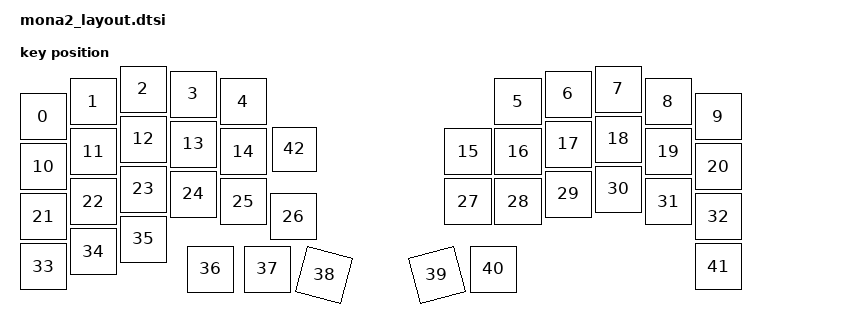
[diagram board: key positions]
// Generated by scripts/keymap.sh: the shield's physical layout plus the wheel, for drawing only.

/ {
physical_layout0: physical_layout_0 {
        compatible = "zmk,physical-layout";
        display-name = "moNa2";

        kscan = <&kscan0>;
        transform = <&default_transform>;

        keys  //                     w   h    x    y     rot    rx    ry
            = <&key_physical_attrs 100 100    0   55       0     0     0>
            , <&key_physical_attrs 100 100  100   25       0     0     0>
            , <&key_physical_attrs 100 100  200    0       0     0     0>
            , <&key_physical_attrs 100 100  300   10       0     0     0>
            , <&key_physical_attrs 100 100  400   25       0     0     0>
            , <&key_physical_attrs 100 100  950   25       0     0     0>
            , <&key_physical_attrs 100 100 1050   10       0     0     0>
            , <&key_physical_attrs 100 100 1150    0       0     0     0>
            , <&key_physical_attrs 100 100 1250   25       0     0     0>
            , <&key_physical_attrs 100 100 1350   55       0     0     0>
            , <&key_physical_attrs 100 100    0  155       0     0     0>
            , <&key_physical_attrs 100 100  100  125       0     0     0>
            , <&key_physical_attrs 100 100  200  100       0     0     0>
            , <&key_physical_attrs 100 100  300  110       0     0     0>
            , <&key_physical_attrs 100 100  400  125       0     0     0>
            , <&key_physical_attrs 100 100  850  125       0     0     0>
            , <&key_physical_attrs 100 100  950  125       0     0     0>
            , <&key_physical_attrs 100 100 1050  110       0     0     0>
            , <&key_physical_attrs 100 100 1150  100       0     0     0>
            , <&key_physical_attrs 100 100 1250  125       0     0     0>
            , <&key_physical_attrs 100 100 1350  155       0     0     0>
            , <&key_physical_attrs 100 100    0  255       0     0     0>
            , <&key_physical_attrs 100 100  100  225       0     0     0>
            , <&key_physical_attrs 100 100  200  200       0     0     0>
            , <&key_physical_attrs 100 100  300  210       0     0     0>
            , <&key_physical_attrs 100 100  400  225       0     0     0>
            , <&key_physical_attrs 100 100  500  255       0     0     0>
            , <&key_physical_attrs 100 100  850  225       0     0     0>
            , <&key_physical_attrs 100 100  950  225       0     0     0>
            , <&key_physical_attrs 100 100 1050  210       0     0     0>
            , <&key_physical_attrs 100 100 1150  200       0     0     0>
            , <&key_physical_attrs 100 100 1250  225       0     0     0>
            , <&key_physical_attrs 100 100 1350  255       0     0     0>
            , <&key_physical_attrs 100 100    0  355       0     0     0>
            , <&key_physical_attrs 100 100  100  325       0     0     0>
            , <&key_physical_attrs 100 100  200  300       0     0     0>
            , <&key_physical_attrs 100 100  335  360       0     0     0>
            , <&key_physical_attrs 100 100  449  360       0     0     0>
            , <&key_physical_attrs 100 100  562  372    1500   612   422>
            , <&key_physical_attrs 100 100  788  372 (-1500)   838   422>
            , <&key_physical_attrs 100 100  901  360       0     0     0>
            , <&key_physical_attrs 100 100 1350  355       0     0     0>
            , <&key_physical_attrs  96  96  505  122       0     0     0>  // wheel
            ;
    };
};
